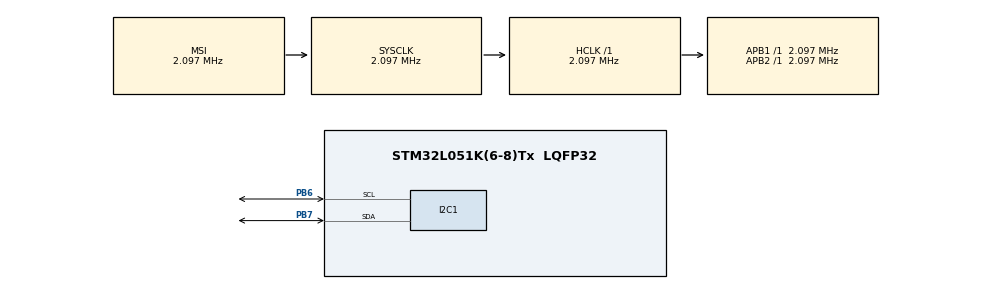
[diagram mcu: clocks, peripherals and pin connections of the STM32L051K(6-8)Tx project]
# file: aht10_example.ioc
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Mcu.Family=STM32L0
Mcu.Name=STM32L051K(6-8)Tx
Mcu.Package=LQFP32
PA13.Mode=Serial_Wire
PA13.Signal=SYS_SWDIO
PA14.Mode=Serial_Wire
PA14.Signal=SYS_SWCLK
PB6.Mode=I2C
PB6.Signal=I2C1_SCL
PB7.Mode=I2C
PB7.Signal=I2C1_SDA
ProjectManager.HeapSize=0x200
ProjectManager.StackSize=0x400
ProjectManager.TargetToolchain=STM32CubeIDE
RCC.AHBFreq_Value=2097000
RCC.APB1Freq_Value=2097000
RCC.APB1TimFreq_Value=2097000
RCC.APB2Freq_Value=2097000
RCC.APB2TimFreq_Value=2097000
RCC.HSI16_VALUE=16000000
RCC.HSI_VALUE=16000000
RCC.LSE_VALUE=32768
RCC.MSI_VALUE=2097000
RCC.SYSCLKFreq_VALUE=2097000
RCC.VCOOutputFreq_Value=48000000
board=custom

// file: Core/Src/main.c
/* USER CODE BEGIN Header */
/**
  ******************************************************************************
  * @file           : main.c
  * @brief          : Main program body
  ******************************************************************************
  * @attention
  *
  * Copyright (c) 2025 STMicroelectronics.
  * All rights reserved.
  *
  * This software is licensed under terms that can be found in the LICENSE file
  * in the root directory of this software component.
  * If no LICENSE file comes with this software, it is provided AS-IS.
  *
  ******************************************************************************
  */
/* USER CODE END Header */
#include "main.h"
#include "i2c.h"
#include "gpio.h"
#include "aht10.h"

/* USER CODE BEGIN PV */
float temp = 0;
float hum = 0;
/* USER CODE END PV */

void SystemClock_Config(void);

int main(void)
{

  /* MCU Configuration--------------------------------------------------------*/

  /* Reset of all peripherals, Initializes the Flash interface and the Systick. */
  HAL_Init();

  /* Configure the system clock */
  SystemClock_Config();

  /* Initialize all configured peripherals */
  MX_GPIO_Init();
  MX_I2C1_Init();
  /* USER CODE BEGIN 2 */
  ahtx0_begin(&hi2c1);
  /* USER CODE END 2 */

  /* Infinite loop */
  while (1)
  {

    /* USER CODE BEGIN 3 */
	  ahtx0_read_sensor();
	  temp = ahtx0_get_temperature();
	  hum = ahtx0_get_humidity();
  }
  /* USER CODE END 3 */
}

void SystemClock_Config(void)
{
  RCC_OscInitTypeDef RCC_OscInitStruct = {0};
  RCC_ClkInitTypeDef RCC_ClkInitStruct = {0};
  RCC_PeriphCLKInitTypeDef PeriphClkInit = {0};

  /** Configure the main internal regulator output voltage
  */
  __HAL_PWR_VOLTAGESCALING_CONFIG(PWR_REGULATOR_VOLTAGE_SCALE1);

  /** Initializes the RCC Oscillators according to the specified parameters
  * in the RCC_OscInitTypeDef structure.
  */
  RCC_OscInitStruct.OscillatorType = RCC_OSCILLATORTYPE_MSI;
  RCC_OscInitStruct.MSIState = RCC_MSI_ON;
  RCC_OscInitStruct.MSICalibrationValue = 0;
  RCC_OscInitStruct.MSIClockRange = RCC_MSIRANGE_5;
  RCC_OscInitStruct.PLL.PLLState = RCC_PLL_NONE;
  if (HAL_RCC_OscConfig(&RCC_OscInitStruct) != HAL_OK)
  {
    Error_Handler();
  }

  /** Initializes the CPU, AHB and APB buses clocks
  */
  RCC_ClkInitStruct.ClockType = RCC_CLOCKTYPE_HCLK|RCC_CLOCKTYPE_SYSCLK
                              |RCC_CLOCKTYPE_PCLK1|RCC_CLOCKTYPE_PCLK2;
  RCC_ClkInitStruct.SYSCLKSource = RCC_SYSCLKSOURCE_MSI;
  RCC_ClkInitStruct.AHBCLKDivider = RCC_SYSCLK_DIV1;
  RCC_ClkInitStruct.APB1CLKDivider = RCC_HCLK_DIV1;
  RCC_ClkInitStruct.APB2CLKDivider = RCC_HCLK_DIV1;

  if (HAL_RCC_ClockConfig(&RCC_ClkInitStruct, FLASH_LATENCY_0) != HAL_OK)
  {
    Error_Handler();
  }
  PeriphClkInit.PeriphClockSelection = RCC_PERIPHCLK_I2C1;
  PeriphClkInit.I2c1ClockSelection = RCC_I2C1CLKSOURCE_PCLK1;
  if (HAL_RCCEx_PeriphCLKConfig(&PeriphClkInit) != HAL_OK)
  {
    Error_Handler();
  }
}

void Error_Handler(void)
{
  __disable_irq();
  while (1)
  {
  }
}
